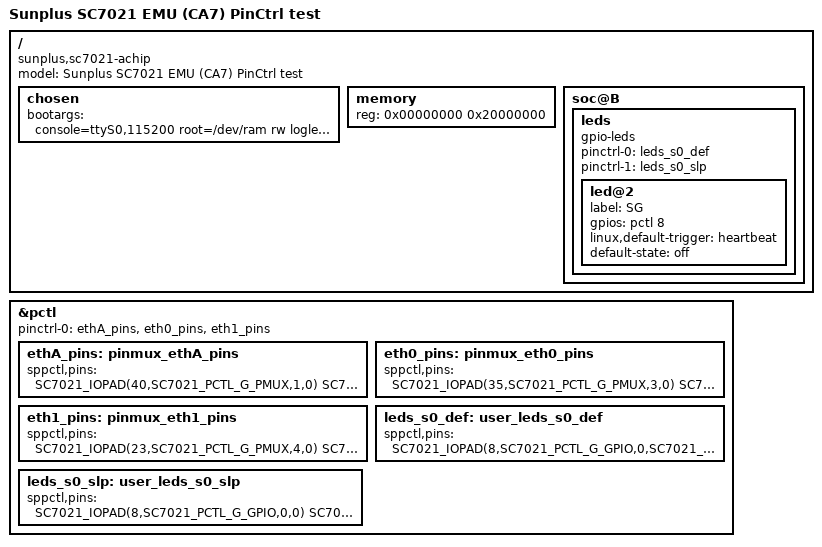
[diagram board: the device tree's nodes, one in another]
/dts-v1/;

#include "pentagram-sp7021-achip.dtsi"

#include <dt-bindings/interrupt-controller/arm-gic.h>

/ {
	model = "Sunplus SC7021 EMU (CA7) PinCtrl test";
	compatible = "sunplus,sc7021-achip";

	chosen {
		bootargs = "console=ttyS0,115200 root=/dev/ram rw loglevel=8 earlyprintk";
	};

	memory {
		reg = <0x00000000 0x20000000>; /* 512MB */
	};
};

&pctl {
 pinctrl-names = "default";
 pinctrl-0 = <&ethA_pins &eth0_pins &eth1_pins>;

 /* for all eth */
 ethA_pins: pinmux_ethA_pins {
  sppctl,pins = <
       SC7021_IOPAD(40,SC7021_PCTL_G_PMUX,1,0)
       SC7021_IOPAD(34,SC7021_PCTL_G_PMUX,2,0)
       SC7021_IOPAD(33,SC7021_PCTL_G_PMUX,7,0)
  >;
 };
 eth0_pins: pinmux_eth0_pins {
  sppctl,pins = <
       SC7021_IOPAD(35,SC7021_PCTL_G_PMUX,3,0)
       SC7021_IOPAD(44,SC7021_PCTL_G_PMUX,5,0)

       SC7021_IOPAD(43,SC7021_PCTL_G_PMUX, 8,0)
       SC7021_IOPAD(41,SC7021_PCTL_G_PMUX, 9,0)
       SC7021_IOPAD(42,SC7021_PCTL_G_PMUX,10,0)
       SC7021_IOPAD(37,SC7021_PCTL_G_PMUX,11,0)
       SC7021_IOPAD(38,SC7021_PCTL_G_PMUX,12,0)
       SC7021_IOPAD(39,SC7021_PCTL_G_PMUX,13,0)
       SC7021_IOPAD(36,SC7021_PCTL_G_PMUX,14,0)
  >;
 };
 eth1_pins: pinmux_eth1_pins {
  sppctl,pins = <
       SC7021_IOPAD(23,SC7021_PCTL_G_PMUX,4,0)
       SC7021_IOPAD(32,SC7021_PCTL_G_PMUX,6,0)

       SC7021_IOPAD(31,SC7021_PCTL_G_PMUX,15,0)
       SC7021_IOPAD(29,SC7021_PCTL_G_PMUX,16,0)
       SC7021_IOPAD(30,SC7021_PCTL_G_PMUX,17,0)
       SC7021_IOPAD(25,SC7021_PCTL_G_PMUX,18,0)
       SC7021_IOPAD(26,SC7021_PCTL_G_PMUX,19,0)
       SC7021_IOPAD(27,SC7021_PCTL_G_PMUX,20,0)
       SC7021_IOPAD(24,SC7021_PCTL_G_PMUX,21,0)
  >;
 };

 leds_s0_def: user_leds_s0_def {
    sppctl,pins = <
      SC7021_IOPAD(8,SC7021_PCTL_G_GPIO,0,SC7021_PCTL_L_INV)
      SC7021_IOPAD(9,SC7021_PCTL_G_GPIO,0,SC7021_PCTL_L_INV)
    >;
 };
 leds_s0_slp: user_leds_s0_slp {
    sppctl,pins = <
      SC7021_IOPAD(8,SC7021_PCTL_G_GPIO,0,0)
      SC7021_IOPAD(9,SC7021_PCTL_G_GPIO,0,0)
    >;
 };
};

/* ----
 next one requires:

 CONFIG_NEW_LEDS=y
 CONFIG_LEDS_CLASS=y
 CONFIG_LEDS_GPIO=y
 CONFIG_LEDS_TRIGGERS=y
 CONFIG_LEDS_TRIGGER_HEARTBEAT=y
*/

/ {
	soc@B {
		leds {
		    pinctrl-names = "default", "sleep";
		    pinctrl-0 = <&leds_s0_def>;
		    pinctrl-1 = <&leds_s0_slp>;
		    compatible = "gpio-leds";
		    led@2 {
			label = "SG";
			gpios = <&pctl 8 GPIO_ACTIVE_HIGH>;
			linux,default-trigger = "heartbeat";
			default-state = "off";
		    };
		};
	};
};
